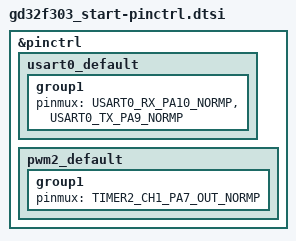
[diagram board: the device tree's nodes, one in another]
/*
 * Copyright (c) 2022, TOKITA Hiroshi <tokita.hiroshi@gmail.com>
 * SPDX-License-Identifier: Apache-2.0
 */

#include <dt-bindings/pinctrl/gd32f303c(b-c-e-g)xx-pinctrl.h>

&pinctrl {
	usart0_default: usart0_default {
		group1 {
			pinmux = <USART0_RX_PA10_NORMP>, <USART0_TX_PA9_NORMP>;
		};
	};

	pwm2_default: pwm2_default {
		group1 {
			pinmux = <TIMER2_CH1_PA7_OUT_NORMP>;
		};
	};
};
